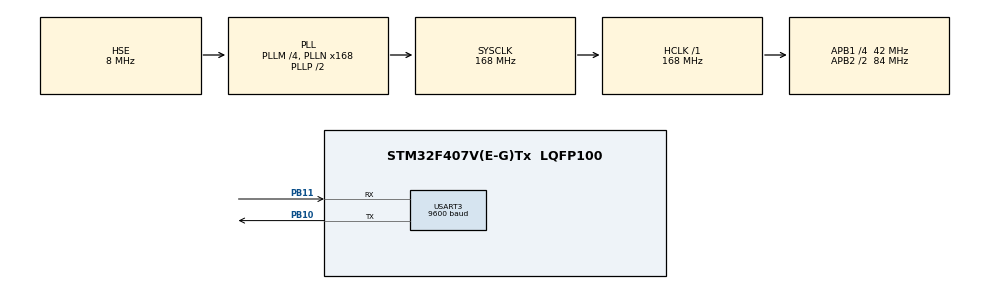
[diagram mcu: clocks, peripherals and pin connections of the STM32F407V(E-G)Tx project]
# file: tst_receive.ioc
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Dma.Request0=USART3_RX
Dma.USART3_RX.0.Direction=DMA_PERIPH_TO_MEMORY
Dma.USART3_RX.0.FIFOMode=DMA_FIFOMODE_DISABLE
Dma.USART3_RX.0.Instance=DMA1_Stream1
Dma.USART3_RX.0.MemDataAlignment=DMA_MDATAALIGN_BYTE
Dma.USART3_RX.0.MemInc=DMA_MINC_ENABLE
Dma.USART3_RX.0.Mode=DMA_CIRCULAR
Dma.USART3_RX.0.PeriphDataAlignment=DMA_PDATAALIGN_BYTE
Dma.USART3_RX.0.PeriphInc=DMA_PINC_DISABLE
Dma.USART3_RX.0.Priority=DMA_PRIORITY_VERY_HIGH
Mcu.Family=STM32F4
Mcu.Name=STM32F407V(E-G)Tx
Mcu.Package=LQFP100
NVIC.DMA1_Stream1_IRQn=true\:0\:0\:false\:false\:true\:false
NVIC.PriorityGroup=NVIC_PRIORITYGROUP_4
PA13.Mode=Trace_Asynchronous_SW
PA13.Signal=SYS_JTMS-SWDIO
PA14.Mode=Trace_Asynchronous_SW
PA14.Signal=SYS_JTCK-SWCLK
PB10.Mode=Asynchronous
PB10.Signal=USART3_TX
PB11.Mode=Asynchronous
PB11.Signal=USART3_RX
PB3.Mode=Trace_Asynchronous_SW
PB3.Signal=SYS_JTDO-SWO
PH0-OSC_IN.Mode=HSE-External-Oscillator
PH0-OSC_IN.Signal=RCC_OSC_IN
PH1-OSC_OUT.Mode=HSE-External-Oscillator
PH1-OSC_OUT.Signal=RCC_OSC_OUT
ProjectManager.HeapSize=0x200
ProjectManager.StackSize=0x400
ProjectManager.TargetToolchain=MDK-ARM V5
RCC.48MHZClocksFreq_Value=84000000
RCC.AHBFreq_Value=168000000
RCC.APB1CLKDivider=RCC_HCLK_DIV4
RCC.APB1Freq_Value=42000000
RCC.APB1TimFreq_Value=84000000
RCC.APB2CLKDivider=RCC_HCLK_DIV2
RCC.APB2Freq_Value=84000000
RCC.APB2TimFreq_Value=168000000
RCC.CortexFreq_Value=168000000
RCC.HCLKFreq_Value=168000000
RCC.HSE_VALUE=8000000
RCC.HSI_VALUE=16000000
RCC.LSE_VALUE=32768
RCC.PLLM=4
RCC.PLLN=168
RCC.PLLSourceVirtual=RCC_PLLSOURCE_HSE
RCC.SYSCLKFreq_VALUE=168000000
RCC.SYSCLKSource=RCC_SYSCLKSOURCE_PLLCLK
RCC.VCOOutputFreq_Value=336000000
USART3.BaudRate=9600
USART3.VirtualMode=VM_ASYNC
board=custom

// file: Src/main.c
/**
  ******************************************************************************
  * @file           : main.c
  * @brief          : Main program body
  ******************************************************************************
  ** This notice applies to any and all portions of this file
  * that are not between comment pairs USER CODE BEGIN and
  * USER CODE END. Other portions of this file, whether
  * inserted by the user or by software development tools
  * are owned by their respective copyright owners.
  *
  * COPYRIGHT(c) 2018 STMicroelectronics
  *
  * Redistribution and use in source and binary forms, with or without modification,
  * are permitted provided that the following conditions are met:
  *   1. Redistributions of source code must retain the above copyright notice,
  *      this list of conditions and the following disclaimer.
  *   2. Redistributions in binary form must reproduce the above copyright notice,
  *      this list of conditions and the following disclaimer in the documentation
  *      and/or other materials provided with the distribution.
  *   3. Neither the name of STMicroelectronics nor the names of its contributors
  *      may be used to endorse or promote products derived from this software
  *      without specific prior written permission.
  *
  * THIS SOFTWARE IS PROVIDED BY THE COPYRIGHT HOLDERS AND CONTRIBUTORS "AS IS"
  * AND ANY EXPRESS OR IMPLIED WARRANTIES, INCLUDING, BUT NOT LIMITED TO, THE
  * IMPLIED WARRANTIES OF MERCHANTABILITY AND FITNESS FOR A PARTICULAR PURPOSE ARE
  * DISCLAIMED. IN NO EVENT SHALL THE COPYRIGHT HOLDER OR CONTRIBUTORS BE LIABLE
  * FOR ANY DIRECT, INDIRECT, INCIDENTAL, SPECIAL, EXEMPLARY, OR CONSEQUENTIAL
  * DAMAGES (INCLUDING, BUT NOT LIMITED TO, PROCUREMENT OF SUBSTITUTE GOODS OR
  * SERVICES; LOSS OF USE, DATA, OR PROFITS; OR BUSINESS INTERRUPTION) HOWEVER
  * CAUSED AND ON ANY THEORY OF LIABILITY, WHETHER IN CONTRACT, STRICT LIABILITY,
  * OR TORT (INCLUDING NEGLIGENCE OR OTHERWISE) ARISING IN ANY WAY OUT OF THE USE
  * OF THIS SOFTWARE, EVEN IF ADVISED OF THE POSSIBILITY OF SUCH DAMAGE.
  *
  ******************************************************************************
  */
#include "main.h"
#include "stm32f4xx_hal.h"
#include "dma.h"
#include "usart.h"
#include "gpio.h"

/* USER CODE BEGIN PV */
/* Private variables ---------------------------------------------------------*/

/* USER CODE END PV */

void SystemClock_Config(void);

/* USER CODE BEGIN PFP */
/* Private function prototypes -----------------------------------------------*/

/* USER CODE END PFP */

/* USER CODE BEGIN 0 */
struct __FILE{
	int handle;
};

FILE __stdout;
FILE __stdin;

int fputc(int ch, FILE *f)
{
	ITM_SendChar(ch);
	return(ch);
}

#define MAX_QUEUE8_SIZE (32)
#define MAX_QUEUE16_SIZE (32)

struct Queue8
{
	uint8_t queue_[MAX_QUEUE8_SIZE];
	uint32_t tail_;
	uint32_t head_;
	uint32_t curr_size_;
};

struct Queue16
{
	int16_t queue_[MAX_QUEUE16_SIZE];
	uint32_t tail_;
	uint32_t head_;
	uint32_t curr_size_;
};

void Queue8_Init(struct Queue8 *q)
{
	q->head_ = 0;
	q->tail_ = 0;
	q->curr_size_ = 0;
}

void Queue8_insert(struct Queue8 *q,uint8_t data)
{
	++q->curr_size_;
	q->queue_[q->head_++] = data;
	q->head_ %= MAX_QUEUE8_SIZE;
}

uint8_t Queue8_lookup(struct Queue8 *q)
{
	if(q->curr_size_)
	{
		--q->curr_size_;
		uint8_t data = q->queue_[q->tail_++];
		q->tail_ %= MAX_QUEUE8_SIZE;
		return data;
	}
	return 0;
}

uint32_t Queue8_length(struct Queue8 *q)
{
	return q->curr_size_;
}

void Queue16_Init(struct Queue16 *q)
{
	q->head_ = 0;
	q->tail_ = 0;
	q->curr_size_ = 0;
}

void Queue16_insert(struct Queue16 *q,int16_t data)
{
	++q->curr_size_;
	q->queue_[q->head_++] = data;
	q->head_ %= MAX_QUEUE16_SIZE;
}

int16_t Queue16_lookup(struct Queue16 *q)
{
	if(q->curr_size_)
	{
		--q->curr_size_;
		int16_t data = q->queue_[q->tail_++];
		q->tail_ %= MAX_QUEUE16_SIZE;
		return data;
	}
	return 0;
}

uint32_t Queue16_length(struct Queue16 *q)
{
	return q->curr_size_;
}

#define NUM_OMEGAS_RECEIVED	(8)
#define MAX_POSSIBLE_OMEGA	(50)

static uint8_t gThinker_Data;
static uint8_t gStart_Byte_Received = 0;
static uint8_t gNum_Data_Received = 0;
static int16_t gOmega;

static struct Queue8 gThinker_Bytes;
static struct Queue16 gThinker_Omegas[4];

void Thinker_Init(void)
{
	HAL_UART_Receive_DMA(&huart3, &gThinker_Data, 1);
	Queue8_Init(&gThinker_Bytes);
	for (uint8_t i = 0; i < 4; ++i) {
		Queue16_Init(&gThinker_Omegas[i]);
	}
}

void get_Thinker(float arr[4])
{
	for (uint8_t i= 0; i < 4; ++i) {
		arr[i] = Queue16_lookup(&gThinker_Omegas[i]);
		arr[i] *= (MAX_POSSIBLE_OMEGA / 32768.0);
	}
}

void HAL_UART_RxCpltCallback(UART_HandleTypeDef *huart)
{
	 if(huart->Instance == USART3)
	 {
		if(!gStart_Byte_Received)
		{
			if (gThinker_Data == 0xA5) {
				gStart_Byte_Received = 1;
			}
		}
		else
		{
			Queue8_insert(&gThinker_Bytes, gThinker_Data);
			++gNum_Data_Received;
			if (gNum_Data_Received == NUM_OMEGAS_RECEIVED) {
				gNum_Data_Received = 0;
				gStart_Byte_Received = 0;
				// Omega calculation using little-endian
				for (uint8_t i = 0; i < 4; ++i) {
					gOmega = (uint16_t)(Queue8_lookup(&gThinker_Bytes) << 8);
					gOmega += (uint16_t)(Queue8_lookup(&gThinker_Bytes));
					Queue16_insert(&gThinker_Omegas[i], gOmega);
				}
			}
		}
	 }
}

/* USER CODE END 0 */

int main(void)
{

  /* MCU Configuration----------------------------------------------------------*/

  /* Reset of all peripherals, Initializes the Flash interface and the Systick. */
  HAL_Init();

  /* Configure the system clock */
  SystemClock_Config();

  /* Initialize all configured peripherals */
  MX_GPIO_Init();
  MX_DMA_Init();
  MX_USART3_UART_Init();
  /* USER CODE BEGIN 2 */
  Thinker_Init();
  HAL_Delay(100);
  printf("Hello World!!\n");

  float curr_omegas[4];
  /* USER CODE END 2 */

  /* Infinite loop */
  /* USER CODE BEGIN WHILE */
  uint32_t sample = HAL_GetTick();
  while (1)
  {
	  if (HAL_GetTick() - sample > 50) {
		  sample = HAL_GetTick();
		  get_Thinker(curr_omegas);
		  for (uint8_t i = 0; i < 4; ++i) {
			  printf("%f  ", curr_omegas[i]);
		  }
		  printf("\n");
	  }

  /* USER CODE END WHILE */

  }

}

void SystemClock_Config(void)
{

  RCC_OscInitTypeDef RCC_OscInitStruct;
  RCC_ClkInitTypeDef RCC_ClkInitStruct;

    /**Configure the main internal regulator output voltage
    */
  __HAL_RCC_PWR_CLK_ENABLE();

  __HAL_PWR_VOLTAGESCALING_CONFIG(PWR_REGULATOR_VOLTAGE_SCALE1);

    /**Initializes the CPU, AHB and APB busses clocks
    */
  RCC_OscInitStruct.OscillatorType = RCC_OSCILLATORTYPE_HSE;
  RCC_OscInitStruct.HSEState = RCC_HSE_ON;
  RCC_OscInitStruct.PLL.PLLState = RCC_PLL_ON;
  RCC_OscInitStruct.PLL.PLLSource = RCC_PLLSOURCE_HSE;
  RCC_OscInitStruct.PLL.PLLM = 4;
  RCC_OscInitStruct.PLL.PLLN = 168;
  RCC_OscInitStruct.PLL.PLLP = RCC_PLLP_DIV2;
  RCC_OscInitStruct.PLL.PLLQ = 4;
  if (HAL_RCC_OscConfig(&RCC_OscInitStruct) != HAL_OK)
  {
    _Error_Handler(__FILE__, __LINE__);
  }

    /**Initializes the CPU, AHB and APB busses clocks
    */
  RCC_ClkInitStruct.ClockType = RCC_CLOCKTYPE_HCLK|RCC_CLOCKTYPE_SYSCLK
                              |RCC_CLOCKTYPE_PCLK1|RCC_CLOCKTYPE_PCLK2;
  RCC_ClkInitStruct.SYSCLKSource = RCC_SYSCLKSOURCE_PLLCLK;
  RCC_ClkInitStruct.AHBCLKDivider = RCC_SYSCLK_DIV1;
  RCC_ClkInitStruct.APB1CLKDivider = RCC_HCLK_DIV4;
  RCC_ClkInitStruct.APB2CLKDivider = RCC_HCLK_DIV2;

  if (HAL_RCC_ClockConfig(&RCC_ClkInitStruct, FLASH_LATENCY_5) != HAL_OK)
  {
    _Error_Handler(__FILE__, __LINE__);
  }

    /**Configure the Systick interrupt time
    */
  HAL_SYSTICK_Config(HAL_RCC_GetHCLKFreq()/1000);

    /**Configure the Systick
    */
  HAL_SYSTICK_CLKSourceConfig(SYSTICK_CLKSOURCE_HCLK);

  /* SysTick_IRQn interrupt configuration */
  HAL_NVIC_SetPriority(SysTick_IRQn, 0, 0);
}

void _Error_Handler(char *file, int line)
{
  while(1)
  {
  }
}

/************************ (C) COPYRIGHT STMicroelectronics *****END OF FILE****/
